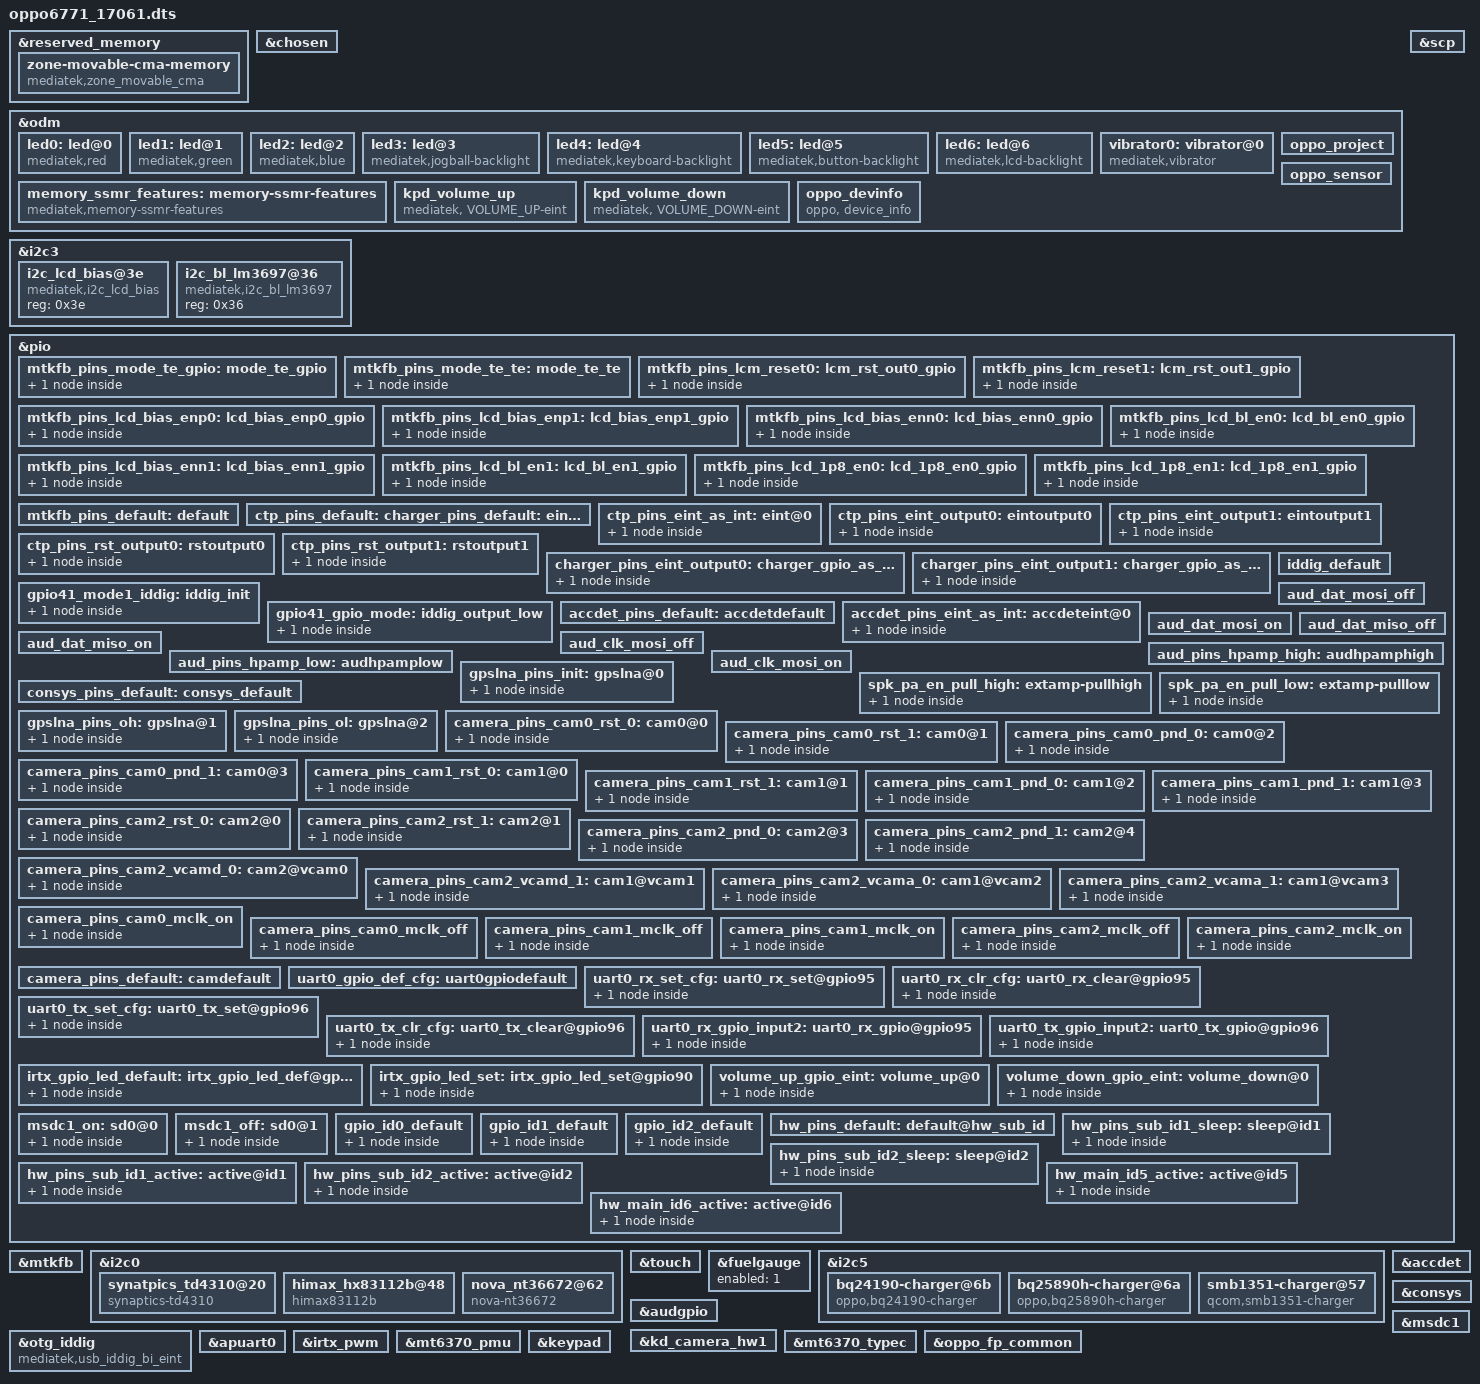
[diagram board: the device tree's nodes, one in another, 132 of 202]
/dts-v1/;
/plugin/;
#include <dt-bindings/interrupt-controller/irq.h>
#include <dt-bindings/interrupt-controller/arm-gic.h>
#include <dt-bindings/pinctrl/mt6771-pinfunc.h>

&reserved_memory {
	#address-cells = <2>;
	#size-cells = <2>;
	ranges;

	zone-movable-cma-memory {
		compatible = "mediatek,zone_movable_cma";
		size = <0 0xffc00000>;
		alignment = <0 0x10000000>;
		alloc-ranges = <0 0xc0000000 1 0x00000000>;

	};
};

/* chosen */
&chosen {
	bootargs = "console=tty0 console=ttyMT0,921600n1 root=/dev/ram \
initrd=0x55000000,0x3000000 loglevel=8 \
androidboot.selinux=permissive androidboot.hardware=mt6771 \
initcall_debug=1";
	/* fpga may has no lk, we need to specify display info here */
	/* fb buffer is reserved using this dts by memory node above */

	atag,videolfb-fb_base_l = <0x5e605000>;
	atag,videolfb-fb_base_h = <0x0>;
	atag,videolfb-islcmfound = <1>;
	atag,videolfb-islcm_inited = <0>;
	atag,videolfb-fps= <6000>;
	atag,videolfb-vramSize= <0x017bb000>;
	atag,videolfb-lcmname= "nt35595_fhd_dsi_cmd_truly_nt50358_drv";
};

&odm {
//#ifdef VENDOR_EDIT
/* Qiao.Hu@BSP.BaseDrv.CHG.Basic, 2017/12/05, Add for charging dtsi */
#include "bat_setting/oppo_17331_mt6771_battery_prop_ext.dtsi"
//endif
	led0:led@0 {
		compatible = "mediatek,red";
		led_mode = <0>;
		data = <1>;
		pwm_config = <0 0 0 0 0>;
	};
	led1:led@1 {
		compatible = "mediatek,green";
		led_mode = <0>;
		data = <1>;
		pwm_config = <0 0 0 0 0>;
	};
	led2:led@2 {
		compatible = "mediatek,blue";
		led_mode = <0>;
		data = <1>;
		pwm_config = <0 0 0 0 0>;
	};
	led3:led@3 {
		compatible = "mediatek,jogball-backlight";
		led_mode = <0>;
		data = <1>;
		pwm_config = <0 0 0 0 0>;
	};
	led4:led@4 {
		compatible = "mediatek,keyboard-backlight";
		led_mode = <0>;
		data = <1>;
		pwm_config = <0 0 0 0 0>;
	};
	led5:led@5 {
		compatible = "mediatek,button-backlight";
		led_mode = <0>;
		data = <1>;
		pwm_config = <0 0 0 0 0>;
	};
	led6:led@6 {
		compatible = "mediatek,lcd-backlight";
		/* #ifndef VENDOR_EDIT */
		/* LiPing-m@PSW.MM.Display.LCD.Machine, 2017/11/03, Add for porting 17331 lcd driver */
		/* led_mode = <5>; */
		/* #else VENDOR_EDIT */
		led_mode = <4>;
		/* #endif VENDOR_EDIT */
		data = <1>;
		pwm_config = <0 3 0 0 0>;
	};
	vibrator0:vibrator@0 {
		compatible = "mediatek,vibrator";
//#ifdef VENDOR_EDIT
//Tong.han@Bsp.Group.Tp,2016/12/16, Modify for vibrator enhance even vibra_time below 9ms
		vib_timer = <30>;
		vib_limit = <0>;
//#else
//		vib_timer = <25>;
//		vib_limit = <9>;
//#endif
//#ifndef VENDOR_EDIT
//Fuchun.Liao@BSP.CHG.Basic 2017/01/04 modify for vib_vol from 2800mv to 3000mv
		//vib_vol= <9>;
//#else
		vib_vol= <11>;
//#endif /* VENDOR_EDIT */
	};
	memory_ssmr_features: memory-ssmr-features {
		compatible = "mediatek,memory-ssmr-features";
		svp-size = <0 0>;
		iris-recognition-size = <0 0>;
		2d_fr-size = <0 0>;
		tui-size = <0 0>;
		wfd-size = <0 0>;
		prot-sharedmem-size = <0 0>;
	};
//#ifndef VENDOR_EDIT
//#Fuchun.Liao@BSP.CHG.Basic 2017/11/22 modify for not use typec
/*
	usb_c_pinctrl:usb_c_pinctrl {
		compatible = "mediatek,usb_c_pinctrl";
	};
*/
//#endif
//ifdef VENDOR_EDIT
/* Bin.Li@EXP.BSP.bootloader.bootflow, 2017/05/16, Add volume up and down */	
	kpd_volume_up:kpd_volume_up {
		compatible = "mediatek, VOLUME_UP-eint";
		interrupt-parent = <&pio>;
		interrupts = <20 IRQ_TYPE_EDGE_FALLING 20 0>;
		debounce = <32000>;
		status = "okay";
	};

	kpd_volume_down:kpd_volume_down {
		compatible = "mediatek, VOLUME_DOWN-eint";
		interrupt-parent = <&pio>;
		interrupts = <94 IRQ_TYPE_EDGE_FALLING 94 0>;
		debounce = <32000>;
		status = "okay";
	};

//#endif





//#ifdef VENDOR_EDIT
/*Bin.Li@EXP.BSP.bootloader.bootflow, 2017/05/15, Add for oppo project */
	oppo_project:oppo_project {
		nProject = <0>;
		nModem = <0>;
		nOperator = <0>;
		nPCBVersion = <0>;
	};
//#endif /*VENDOR_EDIT*/

//#ifdef VENDOR_EDIT
/*Fei.Mo@PSW.BSP.Sensor, 2017/12/18, Add for sensor calibration paramaters */
	oppo_sensor:oppo_sensor {
		gain_als = <0>;
		prox_offset = <0 0>;
		gsensor_sign = <0 0 0>; //1 represent negtive, 0 positive
		gsensor_offset = <0 0 0>;
		gyro_sign = <0 0 0>;//1 represent negtive, 0 positive
		gyro_offset = <0 0 0>;
	};
//#endif /*VENDOR_EDIT*/

//ifdef VENDOR_EDIT
/* Bin.Li@EXP.BSP.bootloader.bootflow, 2017/07/07, Add device-info */
	oppo_devinfo:oppo_devinfo {
		compatible = "oppo, device_info";
	};
//endif
	
};

&scp {
	core_1 = "enable";
	scp_sramSize = <0x00080000>;     /* scp_A_sram_size */
};


/* #ifdef VENDOR_EDIT */
/* LiPing-m@PSW.MM.Display.LCD.Machine, 2017/11/03, Add for porting 17331 lcd driver */
&i2c3 {
    #address-cells = <1>;
    #size-cells = <0>;

       i2c_lcd_bias@3e {
               compatible = "mediatek,i2c_lcd_bias";
               reg = <0x3e>;
               status = "okay";
       };
       i2c_bl_lm3697@36 {
               compatible = "mediatek,i2c_bl_lm3697";
               reg = <0x36>;
               status = "okay";
       };
};

&pio {

	mtkfb_pins_mode_te_gpio: mode_te_gpio {
		pins_cmd_dat {
			pins = <PINMUX_GPIO44__FUNC_GPIO44>;
	};
		};

	mtkfb_pins_mode_te_te: mode_te_te {
		pins_cmd_dat {
			pins = <PINMUX_GPIO44__FUNC_DSI_TE>;
		};
};

	mtkfb_pins_lcm_reset0: lcm_rst_out0_gpio {
		pins_cmd_dat {
			pins = <PINMUX_GPIO45__FUNC_GPIO45>;
			slew-rate = <1>;
			output-low;
		};
};

	mtkfb_pins_lcm_reset1: lcm_rst_out1_gpio {
		pins_cmd_dat {
			pins = <PINMUX_GPIO45__FUNC_GPIO45>;
			slew-rate = <1>;
			output-high;
		};
};

	mtkfb_pins_lcd_bias_enp0: lcd_bias_enp0_gpio {
		pins_cmd_dat {
			pins = <PINMUX_GPIO23__FUNC_GPIO23>;
			slew-rate = <1>;
			output-low;
		};
};

	mtkfb_pins_lcd_bias_enp1: lcd_bias_enp1_gpio {
		pins_cmd_dat {
			pins = <PINMUX_GPIO23__FUNC_GPIO23>;
			slew-rate = <1>;
			output-high;
		};
	};

	mtkfb_pins_lcd_bias_enn0: lcd_bias_enn0_gpio {
		pins_cmd_dat {
			pins = <PINMUX_GPIO24__FUNC_GPIO24>;
			slew-rate = <1>;
			output-low;
		};
	};

	mtkfb_pins_lcd_bias_enn1: lcd_bias_enn1_gpio {
		pins_cmd_dat {
			pins = <PINMUX_GPIO24__FUNC_GPIO24>;
			slew-rate = <1>;
			output-high;
		};
	};

	mtkfb_pins_lcd_bl_en0: lcd_bl_en0_gpio {
		pins_cmd_dat {
			pins = <PINMUX_GPIO66__FUNC_GPIO66>;
			slew-rate = <1>;
			output-low;
		};
	};

	mtkfb_pins_lcd_bl_en1: lcd_bl_en1_gpio {
		pins_cmd_dat {
			pins = <PINMUX_GPIO66__FUNC_GPIO66>;
			slew-rate = <1>;
			output-high;
		};
	};

	mtkfb_pins_lcd_1p8_en0: lcd_1p8_en0_gpio {
		pins_cmd_dat {
			pins = <PINMUX_GPIO65__FUNC_GPIO65>;
			slew-rate = <1>;
			output-low;
		};
	};

	mtkfb_pins_lcd_1p8_en1: lcd_1p8_en1_gpio {
		pins_cmd_dat {
			pins = <PINMUX_GPIO65__FUNC_GPIO65>;
			slew-rate = <1>;
			output-high;
		};
	};

	mtkfb_pins_default: default {
};
};

&mtkfb {
	pinctrl-names = "default", "mode_te_gpio", "mode_te_te", "lcm_rst_out0_gpio",
	"lcm_rst_out1_gpio", "lcd_bias_enp0_gpio", "lcd_bias_enp1_gpio",
	"lcd_bias_enn0_gpio","lcd_bias_enn1_gpio","lcd_bl_en0_gpio",
	"lcd_bl_en1_gpio","lcd_1p8_en0_gpio","lcd_1p8_en1_gpio";
	pinctrl-0 = <&mtkfb_pins_default>;
	pinctrl-1 = <&mtkfb_pins_mode_te_gpio>;
	pinctrl-2 = <&mtkfb_pins_mode_te_te>;
	pinctrl-3 = <&mtkfb_pins_lcm_reset0>;
	pinctrl-4 = <&mtkfb_pins_lcm_reset1>;
	pinctrl-5 = <&mtkfb_pins_lcd_bias_enp0>;
	pinctrl-6 = <&mtkfb_pins_lcd_bias_enp1>;
	pinctrl-7 = <&mtkfb_pins_lcd_bias_enn0>;
	pinctrl-8 = <&mtkfb_pins_lcd_bias_enn1>;
	pinctrl-9 = <&mtkfb_pins_lcd_bl_en0>;
	pinctrl-10 = <&mtkfb_pins_lcd_bl_en1>;
	pinctrl-11 = <&mtkfb_pins_lcd_1p8_en0>;
	pinctrl-12 = <&mtkfb_pins_lcd_1p8_en1>;
	status = "okay";
};
/* #endif VENDOR_EDIT */

//#ifdef VENDOR_EDIT
/* Cong.Dai@PSW.BSP.TP,  2017/06/21, Add for TP td4310*/
&i2c0 {
	#address-cells = <1>;
	#size-cells = <0>;

    synatpics_td4310@20 {
        compatible = "synaptics-td4310";
        reg = <0x20>;
        status = "okay";
        chip-name = "TD4310";

        interrupt-parent = <&pio>;
        interrupts = <1 0x2008 1 0>;

        irq-gpio = <&pio 1 0x2008>;
        //reset-gpio = <&pio 10>;

        pinctrl-names = "default";
        //pinctrl-0 = "&ts_int_active &ts_reset_active";

        touchpanel,max-num-support = <10>;
        touchpanel,tx-rx-num = <18 32>;
        touchpanel,panel-coords = <1080 2160>;
        touchpanel,display-coords = <1080 2160>;

        incell_screen;
        edge_limit_support;
        black_gesture_support;
        //spurious_fingerprint_support;
        //lcd_trigger_fp_check;
        black_gesture_test_support;
        fw_update_app_support;

        /*
        *Virtual Key Config:
        *1:touchpanel,button-type: <virtualkey_type  supportted_button-map>
        *virtualkey_type:
        *Type 1: using board_properties
        *Type 2: using same IC (button zone&& touch zone are seprate)
        *Type 3: using diffrent IC (button zone&& touch zone are seprate)
        *Type 4: No need of virtual key process
        *supportted_button-map:select|menu|home|back
        *
        *2:touchpanel,button-map
        *type (X1,Y1)(X2,Y2)(X3,Y3)(Width_X,Hight_Y)--Only when button-type is 0
        */

        touchpanel,button-type = <2 0x05>;
    };

/* MingQiang.Guo@PSW.BSP.TP,  2017/12/07, Add for TP himax*/
    himax_hx83112b@48 {
        compatible = "himax83112b";
        reg = <0x48>;
        status = "okay";
        chip-name = "HIMAX83112B";

        interrupt-parent = <&pio>;
        interrupts = <1 0x2008 1 0>;

        irq-gpio = <&pio 1 0x2002>;
        reset-gpio = <&pio 42 0x00>;

        pinctrl-names = "default";
        //pinctrl-0 = "&ts_int_active &ts_reset_active";

        touchpanel,max-num-support = <10>;
        touchpanel,tx-rx-num = <16 36>;
        touchpanel,panel-coords = <1080 2280>;
        touchpanel,display-coords = <1080 2280>;

        incell_screen;
        edge_limit_support;
        black_gesture_support;
        fw_update_app_support;

        /*Guohua.Zhong@BSP.TP.Function, 2018/01/04, Add for informing tp driver of usb state*/
        charger_pump_support;
        //spurious_fingerprint_support;
        //lcd_trigger_fp_check;
        black_gesture_test_support;
        touchpanel,button-type = <2 0x05>;
    };

	/* Wanghao@PSW.BSP.TP, 2018/01/22, Add for TP novatek 36672*/
	nova_nt36672@62 {
		compatible = "nova-nt36672";
		reg = <0x62>;
		status = "okay";
		chip-name = "NT36672";

		interrupt-parent = <&pio>;
		interrupts = <1 0x00 1 0>;
		irq-gpio = <&pio 1 0x2001>;

		touchpanel,max-num-support = <10>;
		touchpanel,tx-rx-num = <18 32>;
		touchpanel,panel-coords = <1080 2160>;
		touchpanel,display-coords = <1080 2160>;

		incell_screen;
		edge_limit_support;
		black_gesture_support;
		charger_pump_support;
		//spurious_fingerprint_support;
		//lcd_trigger_fp_check;
		black_gesture_test_support;
		fw_update_app_support;
		//game_switch_support;

		/*
		*Virtual Key Config:
		*1:touchpanel,button-type: <virtualkey_type  supportted_button-map>
		*virtualkey_type:
		*Type 1: using board_properties
		*Type 2: using same IC (button zone&& touch zone are seprate)
		*Type 3: using diffrent IC (button zone&& touch zone are seprate)
		*Type 4: No need of virtual key process
		*supportted_button-map:select|menu|home|back
		*
		*2:touchpanel,button-map
		*type (X1,Y1)(X2,Y2)(X3,Y3)(Width_X,Hight_Y)--Only when button-type is 0
		*/

		touchpanel,button-type = <2 0x05>;
	};
};
//#endif /* VENDOR_EDIT */



/* TOUCH start */
&touch {
	tpd-resolution = <1080 1920>;
	use-tpd-button = <0>;
	tpd-key-num = <3>;
	tpd-key-local= <139 172 158 0>;
	tpd-key-dim-local = <90 883 100 40 230 883 100 40 370 883 100 40 0 0 0 0>;
	tpd-max-touch-num = <5>;
	tpd-filter-enable = <1>;
	tpd-filter-pixel-density = <146>;
	tpd-filter-custom-prameters = <0 0 0 0 0 0 0 0 0 0 0 0>;
	tpd-filter-custom-speed = <0 0 0>;
	pinctrl-names = "default", "state_eint_as_int", "state_eint_output0", "state_eint_output1",
		"state_rst_output0", "state_rst_output1";
	pinctrl-0 = <&ctp_pins_default>;
	pinctrl-1 = <&ctp_pins_eint_as_int>;
	pinctrl-2 = <&ctp_pins_eint_output0>;
	pinctrl-3 = <&ctp_pins_eint_output1>;
	pinctrl-4 = <&ctp_pins_rst_output0>;
	pinctrl-5 = <&ctp_pins_rst_output1>;
	status = "okay";
};
&pio {
	ctp_pins_default: eint0default {
	};
	ctp_pins_eint_as_int: eint@0 {
		pins_cmd_dat {
			pins = <PINMUX_GPIO1__FUNC_GPIO1>;
			slew-rate = <0>;
			bias-disable;
		};
	};
	ctp_pins_eint_output0: eintoutput0 {
		pins_cmd_dat {
			pins = <PINMUX_GPIO1__FUNC_GPIO1>;
			slew-rate = <1>;
			output-low;
		};
	};
	ctp_pins_eint_output1: eintoutput1 {
		pins_cmd_dat {
			pins = <PINMUX_GPIO1__FUNC_GPIO1>;
			slew-rate = <1>;
			output-high;
		};
	};
	ctp_pins_rst_output0: rstoutput0 {
		pins_cmd_dat {
			pins = <PINMUX_GPIO2__FUNC_GPIO2>;
			slew-rate = <1>;
			output-low;
		};
	};
	ctp_pins_rst_output1: rstoutput1 {
		pins_cmd_dat {
			pins = <PINMUX_GPIO2__FUNC_GPIO2>;
			slew-rate = <1>;
			output-high;
		};
	};
};
/* TOUCH end */
//#ifdef VENDOR_EDIT
//PengNan@BSP.CHG.Basic, 2017/09/07, add for compatabling two fuelgauge.
&fuelgauge{
	enabled = <1>;
};
//#endif
//#ifdef VENDOR_EDIT
/* Qiao.Hu@BSP.BaseDrv.CHG.Basic, 2017/11/19, Add for charging */
&i2c5 {
	bq24190-charger@6b {
		status = "okay";
		compatible = "oppo,bq24190-charger";
		reg = <0x6b>;
		chip-name = "BQ24190";
        	interrupt-parent = <&pio>;
        	interrupts = <91 0x2 91 0>;
		pinctrl-names = "default", "charger_gpio_as_output_low", "charger_gpio_as_output_high";
		pinctrl-0 = <&charger_pins_default>;
		pinctrl-1 = <&charger_pins_eint_output0>;
		pinctrl-2 = <&charger_pins_eint_output1>;
		qcom,input_current_charger_ma = <2000>;
		qcom,input_current_usb_ma = <500>;
		qcom,input_current_led_ma = <900>;
		qcom,input_current_led_ma_forcmcc = <500>;
		qcom,input_current_camera_ma = <1200>;

		qcom,input_current_calling_ma = <1500>;
		qcom,iterm-disabled = <0>;
		qcom,iterm-ma = <165>;
		qcom,recharge-mv = <100>;
		qcom,external_gauge;
		qcom,batt_capacity_mah = <3300>;
		qcom,removed_bat_decidegc = <190>;  /* < -19C */
		qcom,cold_bat_decidegc = <30>;  /* -3C ~ 0C */
		qcom,temp_cold_vfloat_mv = <3980>;
		qcom,temp_cold_fastchg_current_ma = <364>;
		qcom,little_cold_bat_decidegc = <0>;	/* 0C ~ 5C */
		qcom,temp_little_cold_vfloat_mv = <4370>;
		qcom,temp_little_cold_fastchg_current_ma = <463>;
		qcom,cool_bat_decidegc = <50>;	/* 5C ~ 12C */
		qcom,temp_cool_vfloat_mv = <4370>;
		qcom,temp_cool_fastchg_current_ma_high = <793>;
		qcom,temp_cool_fastchg_current_ma_low = <463>;
		qcom,little_cool_bat_decidegc = <120>;	/* 12C ~ 22C */
		qcom,temp_little_cool_vfloat_mv = <4370>;
		qcom,temp_little_cool_fastchg_current_ma = <1453>;
		qcom,normal_bat_decidegc = <220>;	/* 22C ~ 45C */
		qcom,temp_normal_fastchg_current_ma = <2113>;
		qcom,temp_normal_vfloat_mv_normalchg = <4370>;
		qcom,temp_normal_vfloat_mv_voocchg = <4370>;
		qcom,warm_bat_decidegc = <450>;		/* 45C ~ 53C */
		qcom,temp_warm_vfloat_mv = <4080>;
		qcom,temp_warm_fastchg_current_ma = <793>;
		qcom,hot_bat_decidegc = <530>;
		qcom,non_standard_vfloat_mv = <4000>;
		qcom,non_standard_fastchg_current_ma = <512>;

		qcom,non_standard_vfloat_sw_limit = <3950>;
		qcom,cold_vfloat_sw_limit = <3930>;
		qcom,little_cold_vfloat_sw_limit = <4320>;
		qcom,cool_vfloat_sw_limit = <4320>;
		qcom,little_cool_vfloat_sw_limit = <4320>;
		qcom,normal_vfloat_sw_limit = <4320>;
		qcom,warm_vfloat_sw_limit = <4030>;
		
		qcom,non_standard_vfloat_over_sw_limit = <3980>;
		qcom,cold_vfloat_over_sw_limit = <3980>;
		qcom,little_cold_vfloat_over_sw_limit = <4390>;
		qcom,cool_vfloat_over_sw_limit = <4390>;
		qcom,little_cool_vfloat_over_sw_limit = <4390>;
		qcom,normal_vfloat_over_sw_limit = <4390>;
		qcom,warm_vfloat_over_sw_limit = <4080>;
		qcom,sw_vfloat_over_protect_enable;

		qcom,max_chg_time_sec = <36000>;
		qcom,charger_hv_thr = <5800>;
		qcom,charger_lv_thr = <3400>;
		qcom,vbatt_full_thr = <4400>;
		qcom,vbatt_hv_thr = <4500>;
		qcom,vfloat_step_mv = <16>;
	//	qcom,suspend_after_full;
		qcom,check_batt_full_by_sw;
		qcom,chg_ctrl_by_calling;
		qcom,chg_ctrl_by_lcd;
		qcom,chg_ctrl_by_camera;
		/*Qiao.Hu@EXP.BSP.LCD.Machine, 2017/07/20, Add  function for chargerid distinguish*/
		qcom,usb_shell_ctrl;
		qcom,usb_enum_enable;
		qcom,usb_switch_gpio 		= <&pio 9 0x00>;
		qcom,usb_shell_ctrl_gpio 			= <&pio 21 0x00>;
	};
	bq25890h-charger@6a {
		status = "okay";
		compatible = "oppo,bq25890h-charger";
		reg = <0x6a>;
		chip-name = "BQ25890H";
        interrupt-parent = <&pio>;
        interrupts = <91 0x2 91 0>;
		pinctrl-names = "default", "charger_gpio_as_output_low", "charger_gpio_as_output_high", "ship_sleep", "ship_active";
		pinctrl-0 = <&charger_pins_default>;
		pinctrl-1 = <&charger_pins_eint_output0>;
		pinctrl-2 = <&charger_pins_eint_output1>;
		pinctrl-3 = <&ship_sleep_gpio>;
		pinctrl-4 = <&ship_active_gpio>;
		qcom,input_current_charger_ma = <2000>;
		qcom,input_current_usb_ma = <500>;
		qcom,input_current_led_ma = <900>;
		qcom,input_current_led_ma_forcmcc = <500>;
		qcom,input_current_camera_ma = <1200>;

		qcom,input_current_calling_ma = <1500>;
		qcom,iterm-disabled = <0>;
		qcom,iterm-ma = <165>;
		qcom,recharge-mv = <100>;
		qcom,external_gauge;
		qcom,batt_capacity_mah = <3300>;
		qcom,removed_bat_decidegc = <190>;  /* < -19C */
		qcom,cold_bat_decidegc = <30>;  /* -3C ~ 0C */
		qcom,temp_cold_vfloat_mv = <3980>;
		qcom,temp_cold_fastchg_current_ma = <364>;
		qcom,little_cold_bat_decidegc = <0>;	/* 0C ~ 5C */
		qcom,temp_little_cold_vfloat_mv = <4370>;
		qcom,temp_little_cold_fastchg_current_ma = <463>;
		qcom,cool_bat_decidegc = <50>;	/* 5C ~ 12C */
		qcom,temp_cool_vfloat_mv = <4370>;
		qcom,temp_cool_fastchg_current_ma_high = <793>;
		qcom,temp_cool_fastchg_current_ma_low = <463>;
		qcom,little_cool_bat_decidegc = <120>;	/* 12C ~ 22C */
		qcom,temp_little_cool_vfloat_mv = <4370>;
		qcom,temp_little_cool_fastchg_current_ma = <1453>;
		qcom,normal_bat_decidegc = <220>;	/* 22C ~ 45C */
		qcom,temp_normal_fastchg_current_ma = <2113>;
		qcom,temp_normal_vfloat_mv_normalchg = <4370>;
		qcom,temp_normal_vfloat_mv_voocchg = <4370>;
		qcom,warm_bat_decidegc = <450>;		/* 45C ~ 53C */
		qcom,temp_warm_vfloat_mv = <4080>;
		qcom,temp_warm_fastchg_current_ma = <793>;
		qcom,hot_bat_decidegc = <530>;
		qcom,non_standard_vfloat_mv = <4000>;
		qcom,non_standard_fastchg_current_ma = <512>;

		qcom,non_standard_vfloat_sw_limit = <3950>;
		qcom,cold_vfloat_sw_limit = <3930>;
		qcom,little_cold_vfloat_sw_limit = <4320>;
		qcom,cool_vfloat_sw_limit = <4320>;
		qcom,little_cool_vfloat_sw_limit = <4320>;
		qcom,normal_vfloat_sw_limit = <4320>;
		qcom,warm_vfloat_sw_limit = <4030>;
		
		qcom,non_standard_vfloat_over_sw_limit = <3980>;
		qcom,cold_vfloat_over_sw_limit = <3980>;
		qcom,little_cold_vfloat_over_sw_limit = <4390>;
		qcom,cool_vfloat_over_sw_limit = <4390>;
		qcom,little_cool_vfloat_over_sw_limit = <4390>;
		qcom,normal_vfloat_over_sw_limit = <4390>;
		qcom,warm_vfloat_over_sw_limit = <4080>;
		qcom,sw_vfloat_over_protect_enable;

		qcom,max_chg_time_sec = <36000>;
		qcom,charger_hv_thr = <5800>;
		qcom,charger_lv_thr = <3400>;
		qcom,vbatt_full_thr = <4400>;
		qcom,vbatt_hv_thr = <4500>;
		qcom,vfloat_step_mv = <16>;
	//	qcom,suspend_after_full;
		qcom,check_batt_full_by_sw;
		qcom,chg_ctrl_by_calling;
		qcom,chg_ctrl_by_lcd;
		qcom,chg_ctrl_by_camera;
		/*Qiao.Hu@EXP.BSP.LCD.Machine, 2017/07/20, Add  function for chargerid distinguish*/
		qcom,usb_shell_ctrl;
		qcom,usb_switch_gpio 		= <&pio 9 0x00>;
		qcom,ship_gpio 		= <&pio 152 0x00>;
		qcom,usb_shell_ctrl_gpio 			= <&pio 21 0x00>;
	};
	smb1351-charger@57 {
		status = "okay";
		compatible = "qcom,smb1351-charger";
		reg = <0x57>;
		pinctrl-names = "default", "charger_gpio_as_output_low", "charger_gpio_as_output_high", "ship_sleep", "ship_active";
		pinctrl-0 = <&charger_pins_default>;
		pinctrl-1 = <&charger_pins_eint_output0>;
		pinctrl-2 = <&charger_pins_eint_output1>;
		pinctrl-3 = <&ship_sleep_gpio>;
		pinctrl-4 = <&ship_active_gpio>;
		qcom,input_current_charger_ma = <2000>;
		qcom,input_current_usb_ma = <500>;
		qcom,input_current_led_ma = <900>;
		qcom,input_current_led_ma_forcmcc = <500>;
		qcom,input_current_camera_ma = <1200>;

		qcom,input_current_calling_ma = <1500>;
		qcom,iterm-disabled = <0>;
		qcom,iterm-ma = <172>;
		qcom,recharge-mv = <100>;
		qcom,external_gauge;
		qcom,batt_capacity_mah = <3450>;
		qcom,removed_bat_decidegc = <190>;  /* < -19C */
		qcom,cold_bat_decidegc = <30>;  /* -3C ~ 0C */
		qcom,temp_cold_vfloat_mv = <3980>;
		qcom,temp_cold_fastchg_current_ma = <364>;
		qcom,little_cold_bat_decidegc = <0>;	/* 0C ~ 5C */
		qcom,temp_little_cold_vfloat_mv = <4380>;
		qcom,temp_little_cold_fastchg_current_ma = <485>;
		qcom,cool_bat_decidegc = <50>;	/* 5C ~ 12C */
		qcom,temp_cool_vfloat_mv = <4380>;
		qcom,temp_cool_fastchg_current_ma_high = <830>;
		qcom,temp_cool_fastchg_current_ma_low = <485>;
		qcom,little_cool_bat_decidegc = <120>;	/* 12C ~ 22C */
		qcom,temp_little_cool_vfloat_mv = <4380>;
		qcom,temp_little_cool_fastchg_current_ma = <1520>;
		qcom,normal_bat_decidegc = <220>;	/* 22C ~ 45C */
		qcom,temp_normal_fastchg_current_ma = <2210>;
		qcom,temp_normal_vfloat_mv_normalchg = <4380>;
		qcom,temp_normal_vfloat_mv_voocchg = <4380>;
		qcom,warm_bat_decidegc = <450>;		/* 45C ~ 53C */
		qcom,temp_warm_vfloat_mv = <4080>;
		qcom,temp_warm_fastchg_current_ma = <830>;
		qcom,hot_bat_decidegc = <530>;
		qcom,non_standard_vfloat_mv = <4000>;
		qcom,non_standard_fastchg_current_ma = <512>;

		qcom,non_standard_vfloat_sw_limit = <3960>;
		qcom,cold_vfloat_sw_limit = <3940>;
		qcom,little_cold_vfloat_sw_limit = <4320>;
		qcom,cool_vfloat_sw_limit = <4320>;
		qcom,little_cool_vfloat_sw_limit = <4320>;
		qcom,normal_vfloat_sw_limit = <4320>;
		qcom,warm_vfloat_sw_limit = <4030>;
		
		qcom,non_standard_vfloat_over_sw_limit = <3980>;
		qcom,cold_vfloat_over_sw_limit = <3980>;
		qcom,little_cold_vfloat_over_sw_limit = <4380>;
		qcom,cool_vfloat_over_sw_limit = <4380>;
		qcom,little_cool_vfloat_over_sw_limit = <4380>;
		qcom,normal_vfloat_over_sw_limit = <4380>;
		qcom,warm_vfloat_over_sw_limit = <4080>;
		qcom,sw_vfloat_over_protect_enable;

		qcom,max_chg_time_sec = <36000>;
		qcom,charger_hv_thr = <5800>;
		qcom,charger_lv_thr = <3400>;
		qcom,vbatt_full_thr = <4400>;
		qcom,vbatt_hv_thr = <4500>;
		qcom,vfloat_step_mv = <16>;
	//	qcom,suspend_after_full;
		qcom,check_batt_full_by_sw;
		qcom,chg_ctrl_by_calling;
		qcom,chg_ctrl_by_lcd;
		qcom,chg_ctrl_by_camera;
		/*Qiao.Hu@EXP.BSP.LCD.Machine, 2017/07/20, Add  function for chargerid distinguish*/
		qcom,usb_shell_ctrl;
		qcom,usb_switch_gpio 		= <&pio 9 0x00>;
		qcom,usb_shell_ctrl_gpio 			= <&pio 21 0x00>;
	};
};

&pio {
	charger_pins_default: eint0default {
	};
	charger_pins_eint_output0: charger_gpio_as_output_low {
		pins_cmd_dat {
			pins = <PINMUX_GPIO9__FUNC_GPIO9>;
			slew-rate = <1>;
			output-low;
		};
	};
	charger_pins_eint_output1: charger_gpio_as_output_high {
		pins_cmd_dat {
			pins = <PINMUX_GPIO9__FUNC_GPIO9>;
			slew-rate = <1>;
			output-high;
		};
	};
};
//#endif /* VENDOR_EDIT */
/* Qiao.Hu@@Prd6.BaseDrv.USB.Basic, 2017/07/25, Add for otg */
&otg_iddig {
	/* Qiao.Hu@EXP.BSP.CHG.basic, 2017/05/09, Add for otg support */
	compatible = "mediatek,usb_iddig_bi_eint";
	pinctrl-names = "iddig_default", "iddig_init", "iddig_output_low" ;
	pinctrl-0 = <&iddig_default>;
	pinctrl-1 = <&gpio41_mode1_iddig>;
	pinctrl-2 = <&gpio41_gpio_mode>;
	status = "okay";
    	/* Qiao.Hu@EXP.BSP.CHG.basic, 2017/05/25, Add for OTG GPIO */
	qcom,otg_switch_gpio = <41>;

};
&pio {
	iddig_default: iddig_default {
	};
	//#ifdef VENDOR_EDIT
	/* Qiao.Hu@EXP.BSP.CHG.basic, 2017/11/28, Add for otg support */
	gpio41_mode1_iddig: iddig_init {
		pins_cmd_dat {
			pins = <PINMUX_GPIO41__FUNC_IDDIG>;
			slew-rate = <0>;
			bias-pull-up = <101>;
		};
	};
	gpio41_gpio_mode: iddig_output_low {
		pins_cmd_dat {
			pins = <PINMUX_GPIO41__FUNC_GPIO41>;
			slew-rate = <1>;
			output-low;
		};
	};

	//#endif /* VENDOR_EDIT */
};


/* accdet start */
&accdet {
	/* accdet micbias voltage: 0x07,2.7v;0x05,2.5v;0x02,1.9v */
	//#ifdef VENDOR_EDIT
	//Yongzhi.Zhang@PSW.MM.AudioDriver.Codec, 2018/03/10,
	//modify for changing micbias vol to 2.7V for headset mic
	accdet-mic-vol = <7>;
	//#else /* VENDOR_EDIT */
	//accdet-mic-vol = <6>;
	//#endif /* VENDOR_EDIT */
	headset-mode-setting = <0x500 0x500 1 0x1f0 0x800 0x800 0x20 0x44>;
	accdet-plugout-debounce = <1>;
	/*1:ACC mode, 2:low cost without in bias, 6:low cost with in bias*/
	//#ifdef VENDOR_EDIT
	//Yongzhi.Zhang@PSW.MM.AudioDriver.HeadsetDet, 2017/12/28, Modify for ACC MODE
	accdet-mic-mode = <1>;
	//#else /* VENDOR_EDIT */
	//accdet-mic-mode = <2>;
	//#endif /* VENDOR_EDIT */
	/* eint_level_trigger: 8,LEVEL_LOW(default);4,LEVEL_HIGH;others,LEVEL_LOW */
	headset-eint-level-pol = <8>;
	/*0--MD_MAX--UP_MAX--DW_MAX*/
	//#ifdef VENDOR_EDIT
	//Yongzhi.Zhang@PSW.MM.AudioDriver.HeadsetDet, 2017/14/14, Modify for support headset key
	headset-three-key-threshold = <0 82 170 306>;
	//#else /* VENDOR_EDIT */
	//headset-three-key-threshold = <0 80 220 400>;
	//#endif /* VENDOR_EDIT */
	headset-three-key-threshold-CDD = <0 121 192 600>;
	/*0--MD_MAX--VOICE_MAX--UP_MAX--DW_MAX*/
	headset-four-key-threshold = <0 58 121 192 400>;
	/*moisture external resister ohm*/
	moisture-external-r = <2000000>;
	/*moisture internal resister ohm*/
	moisture-internal-r = <47000>;
	/*moisture of water resister ohm*/
	moisture-water-r = <10000>;
	/* ACCDET GPIO standardization ACC mode no use */
	pinctrl-names = "default", "state_eint_as_int";
	pinctrl-0 = <&accdet_pins_default>;
	pinctrl-1 = <&accdet_pins_eint_as_int>;
	status = "okay";
};
&pio {
	accdet_pins_default: accdetdefault {
	};
	accdet_pins_eint_as_int: accdeteint@0 {
		pins_cmd_dat {
			/*pins = <PINMUX_GPIO7__FUNC_GPIO7>;*/
			slew-rate = <0>;
			bias-disable;
		};
	};
};
/* accdet end */

//#ifdef VENDOR_EDIT
/* Yongzhi.Zhang@PSW.MM.AudioDriver.Machine, 2017/11/22,
 * Modify for audio gpio config */
&audgpio {
	pinctrl-names = "aud_dat_mosi_off",
			"aud_dat_mosi_on",
			"aud_dat_miso_off",
			"aud_dat_miso_on",
			"hpamp-pullhigh",
			"hpamp-pulllow",
			"aud_clk_mosi_off",
			"aud_clk_mosi_on",
			"extamp-pullhigh",
			"extamp-pulllow";
	pinctrl-0 = <&aud_dat_mosi_off>;
	pinctrl-1 = <&aud_dat_mosi_on>;
	pinctrl-2 = <&aud_dat_miso_off>;
	pinctrl-3 = <&aud_dat_miso_on>;
	pinctrl-4 = <&aud_pins_hpamp_high>;
	pinctrl-5 = <&aud_pins_hpamp_low>;
	pinctrl-6 = <&aud_clk_mosi_off>;
	pinctrl-7 = <&aud_clk_mosi_on>;
	pinctrl-8 = <&spk_pa_en_pull_high>;
	pinctrl-9 = <&spk_pa_en_pull_low>;
	gpio_spk_pa_en = <&pio 153 0>;
	status = "okay";
};

&pio {
	aud_dat_mosi_off: aud_dat_mosi_off {
	};

	aud_dat_mosi_on: aud_dat_mosi_on {
	};

	aud_dat_miso_off: aud_dat_miso_off {
	};

	aud_dat_miso_on: aud_dat_miso_on {
	};

	aud_pins_hpamp_high: audhpamphigh {
	};

	aud_pins_hpamp_low: audhpamplow {
	};

	aud_clk_mosi_off: aud_clk_mosi_off {
	};

	aud_clk_mosi_on: aud_clk_mosi_on {
	};

	spk_pa_en_pull_high: extamp-pullhigh {
		pins_cmd_dat {
			pins = <PINMUX_GPIO153__FUNC_GPIO153>;
			slew-rate = <1>;
			output-high;
		};
	};

	spk_pa_en_pull_low: extamp-pulllow {
		pins_cmd_dat {
			pins = <PINMUX_GPIO153__FUNC_GPIO153>;
			slew-rate = <1>;
			output-low;
		};
	};
};
//#endif /* VENDOR_EDIT */

/* CONSYS GPIO standardization */
&pio {
	consys_pins_default: consys_default {
	};
	gpslna_pins_init: gpslna@0 {
		pins_cmd_dat {
			pins = <PINMUX_GPIO169__FUNC_GPIO169>;
			//#ifndef VENDOR_EDIT
			//Wenjie.Liu@PSW.CN.GPS.Hardware.Power.1202743, 2017/12/29,
			//modify for: [GPS_LNA gpio's output direction is out]
			/*
			slew-rate = <0>;
			*/
			//#else /* VENDOR_EDIT */
			slew-rate = <1>;
			//#endif /* VENDOR_EDIT */
			bias-disable;
			output-low;
		};
	};
	gpslna_pins_oh: gpslna@1 {
		pins_cmd_dat {
			pins = <PINMUX_GPIO169__FUNC_GPIO169>;
			slew-rate = <1>;
			output-high;
		};
	};
	gpslna_pins_ol: gpslna@2 {
		pins_cmd_dat {
			pins = <PINMUX_GPIO169__FUNC_GPIO169>;
			slew-rate = <1>;
			output-low;
		};
	};
};
&consys {
	pinctrl-names = "default", "gps_lna_state_init", "gps_lna_state_oh", "gps_lna_state_ol";
	pinctrl-0 = <&consys_pins_default>;
	pinctrl-1 = <&gpslna_pins_init>;
	pinctrl-2 = <&gpslna_pins_oh>;
	pinctrl-3 = <&gpslna_pins_ol>;
	status = "okay";
};
/* CONSYS end */

/* CAMERA GPIO standardization */
&pio {
	camera_pins_cam0_rst_0: cam0@0 {
		pins_cmd_dat {
			pins = <PINMUX_GPIO101__FUNC_GPIO101>;
			slew-rate = <1>; /*direction 0:in, 1:out*/
			output-low;/*direction out used only. output_low or high*/
		};
	};
	camera_pins_cam0_rst_1: cam0@1 {
		pins_cmd_dat {
			pins = <PINMUX_GPIO101__FUNC_GPIO101>;
			slew-rate = <1>;
			output-high;
		};
	};
	camera_pins_cam0_pnd_0: cam0@2 {
		pins_cmd_dat {
			pins = <PINMUX_GPIO97__FUNC_GPIO97>;
			slew-rate = <1>;
			output-low;
		};
	};
	camera_pins_cam0_pnd_1: cam0@3 {
		pins_cmd_dat {
			pins = <PINMUX_GPIO97__FUNC_GPIO97>;
			slew-rate = <1>;
			output-high;
		};
	};
	camera_pins_cam1_rst_0: cam1@0 {
		pins_cmd_dat {
			pins = <PINMUX_GPIO102__FUNC_GPIO102>;
			slew-rate = <1>; /*direction 0:in, 1:out*/
			output-low;/*direction out used only. output_low or high*/
		};
	};
	camera_pins_cam1_rst_1: cam1@1 {
		pins_cmd_dat {
			pins = <PINMUX_GPIO102__FUNC_GPIO102>;
			slew-rate = <1>;
			output-high;
		};
	};
	camera_pins_cam1_pnd_0: cam1@2 {
		pins_cmd_dat {
			pins = <PINMUX_GPIO98__FUNC_GPIO98>;
			slew-rate = <1>;
			output-low;
		};
	};
	camera_pins_cam1_pnd_1: cam1@3 {
		pins_cmd_dat {
			pins = <PINMUX_GPIO98__FUNC_GPIO98>;
			slew-rate = <1>;
			output-high;
		};
	};
	camera_pins_cam2_rst_0: cam2@0 {
		pins_cmd_dat {
			pins = <PINMUX_GPIO109__FUNC_GPIO109>;
			slew-rate = <1>;
			output-low;
		};
	};
	camera_pins_cam2_rst_1: cam2@1 {
		pins_cmd_dat {
			pins = <PINMUX_GPIO109__FUNC_GPIO109>;
			slew-rate = <1>;
			output-high;
		};
	};
	camera_pins_cam2_pnd_0: cam2@3 {
		pins_cmd_dat {
			pins = <PINMUX_GPIO107__FUNC_GPIO107>;
			slew-rate = <1>;
			output-low;
		};
	};
	camera_pins_cam2_pnd_1: cam2@4 {
		pins_cmd_dat {
			pins = <PINMUX_GPIO107__FUNC_GPIO107>;
			slew-rate = <1>;
			output-high;
		};
	};
	camera_pins_cam2_vcamd_0: cam2@vcam0 {
		pins_cmd_dat {
			pins = <PINMUX_GPIO169__FUNC_GPIO169>;
			slew-rate = <1>;
			output-low;
		};
	};
	camera_pins_cam2_vcamd_1: cam1@vcam1 {
		pins_cmd_dat {
			pins = <PINMUX_GPIO169__FUNC_GPIO169>;
			slew-rate = <1>;
			output-high;
		};
	};
	camera_pins_cam2_vcama_0: cam1@vcam2 {
		pins_cmd_dat {
			pins = <PINMUX_GPIO169__FUNC_GPIO169>;
			slew-rate = <1>;
			output-low;
		};
	};
	camera_pins_cam2_vcama_1: cam1@vcam3 {
		pins_cmd_dat {
			pins = <PINMUX_GPIO169__FUNC_GPIO169>;
			slew-rate = <1>;
			output-high;
		};
	};
	camera_pins_cam0_mclk_on: camera_pins_cam0_mclk_on {
		pins_cmd_dat {
			pins = <PINMUX_GPIO99__FUNC_CMMCLK0>;
		};
	};
	camera_pins_cam0_mclk_off: camera_pins_cam0_mclk_off {
		pins_cmd_dat {
			pins = <PINMUX_GPIO99__FUNC_GPIO99>;
		};
	};
	camera_pins_cam1_mclk_off: camera_pins_cam1_mclk_off {
		pins_cmd_dat {
			pins = <PINMUX_GPIO100__FUNC_GPIO100>;
		};
	};
	camera_pins_cam1_mclk_on: camera_pins_cam1_mclk_on {
		pins_cmd_dat {
			pins = <PINMUX_GPIO100__FUNC_CMMCLK1>;
		};
	};
	camera_pins_cam2_mclk_off: camera_pins_cam2_mclk_off {
		pins_cmd_dat {
			pins = <PINMUX_GPIO108__FUNC_GPIO108>;
		};
	};
	camera_pins_cam2_mclk_on: camera_pins_cam2_mclk_on {
		pins_cmd_dat {
			pins = <PINMUX_GPIO108__FUNC_CMMCLK2>;
		};
	};
	camera_pins_default: camdefault {
	};
};
&kd_camera_hw1 {
	pinctrl-names = "default",
			"cam0_rst0", "cam0_rst1",
			"cam0_pnd0", "cam0_pnd1",
			"cam1_rst0", "cam1_rst1",
			"cam1_pnd0", "cam1_pnd1",
			"cam2_rst0", "cam2_rst1",
			"cam2_pnd0", "cam2_pnd1",
			"cam_ldo_main2_vcamd_0", "cam_ldo_main2_vcamd_1",
			"cam_ldo_main2_vcama_0", "cam_ldo_main2_vcama_1",
			"cam0_mclk_off", "cam0_mclk_on",
			"cam1_mclk_off", "cam1_mclk_on",
			"cam2_mclk_off", "cam2_mclk_on";
	pinctrl-0 = <&camera_pins_default>;
	pinctrl-1 = <&camera_pins_cam0_rst_0>;
	pinctrl-2 = <&camera_pins_cam0_rst_1>;
	pinctrl-3 = <&camera_pins_cam0_pnd_0>;
	pinctrl-4 = <&camera_pins_cam0_pnd_1>;
	pinctrl-5 = <&camera_pins_cam1_rst_0>;
	pinctrl-6 = <&camera_pins_cam1_rst_1>;
	pinctrl-7 = <&camera_pins_cam1_pnd_0>;
	pinctrl-8 = <&camera_pins_cam1_pnd_1>;
	pinctrl-9 = <&camera_pins_cam2_rst_0>;
	pinctrl-10 = <&camera_pins_cam2_rst_1>;
	pinctrl-11 = <&camera_pins_cam2_pnd_0>;
	pinctrl-12 = <&camera_pins_cam2_pnd_1>;
	pinctrl-13 = <&camera_pins_cam2_vcamd_0>;
	pinctrl-14 = <&camera_pins_cam2_vcamd_1>;
	pinctrl-15 = <&camera_pins_cam2_vcama_0>;
	pinctrl-16 = <&camera_pins_cam2_vcama_1>;
	pinctrl-17 = <&camera_pins_cam0_mclk_off>;
	pinctrl-18 = <&camera_pins_cam0_mclk_on>;
	pinctrl-19 = <&camera_pins_cam1_mclk_off>;
	pinctrl-20 = <&camera_pins_cam1_mclk_on>;
	pinctrl-21 = <&camera_pins_cam2_mclk_off>;
	pinctrl-22 = <&camera_pins_cam2_mclk_on>;

	status = "okay";
};

/* UART GPIO */
&apuart0 {
	pinctrl-names = "uart0_gpio_default",
			"uart0_rx_set",
			"uart0_rx_clear",
			"uart0_tx_set",
			"uart0_tx_clear",
			//#ifdef VENDOR_EDIT
			//PengNan@BSP.CHG.Basic, 2017/08/10, add for switch uart mode for chargerid.
			"uart0_rx_gpio",
			"uart0_tx_gpio";
			//#endif /*VENDOR_EDIT*/
	pinctrl-0 = <&uart0_gpio_def_cfg>;
	pinctrl-1 = <&uart0_rx_set_cfg>;
	pinctrl-2 = <&uart0_rx_clr_cfg>;
	pinctrl-3 = <&uart0_tx_set_cfg>;
	pinctrl-4 = <&uart0_tx_clr_cfg>;
	//#ifdef VENDOR_EDIT
	//Qiao.Hu@BSP.CHG.Basic, 2017/12/18, add for switch uart mode for chargerid.
	pinctrl-5 = <&uart0_rx_gpio_input2>;
	pinctrl-6 = <&uart0_tx_gpio_input2>;
	//#endif /*VENDOR_EDIT*/
	status = "okay";
};

&pio {
	/* UART GPIO Settings - Start */
	/* UART0: rx set, rx clear, tx clear, tx clear*/
	uart0_gpio_def_cfg:uart0gpiodefault {

	};
	uart0_rx_set_cfg:uart0_rx_set@gpio95 {
		pins_cmd_dat {
			pins = <PINMUX_GPIO95__FUNC_URXD0>;
		};
	};
	uart0_rx_clr_cfg:uart0_rx_clear@gpio95 {
		pins_cmd_dat {
			pins = <PINMUX_GPIO95__FUNC_GPIO95>;
			slew-rate = <1>;
			output-high;
		};
	};
	uart0_tx_set_cfg:uart0_tx_set@gpio96 {
		pins_cmd_dat {
			pins = <PINMUX_GPIO96__FUNC_UTXD0>;
		};
	};
	uart0_tx_clr_cfg:uart0_tx_clear@gpio96 {
		pins_cmd_dat {
			pins = <PINMUX_GPIO96__FUNC_GPIO96>;
			slew-rate = <1>;
			output-high;
		};
	};
	//#ifdef VENDOR_EDIT
	//Qiao.Hu@BSP.CHG.Basic, 2017/12/18, add for switch uart mode for chargerid.
	uart0_rx_gpio_input2:uart0_rx_gpio@gpio95 {
		pins_cmd_dat {
			pins = <PINMUX_GPIO95__FUNC_GPIO95>;
			input-enable;
			slew-rate = <0>;
			bias-disable;
		};
	};
	uart0_tx_gpio_input2:uart0_tx_gpio@gpio96 {
		pins_cmd_dat {
			pins = <PINMUX_GPIO96__FUNC_GPIO96>;
			input-enable;
			slew-rate = <0>;
			bias-disable;
		};
	};
	//#endif /*VENDOR_EDIT*/
};/* UART GPIO end */

/* IRTX GPIO Start */
&irtx_pwm {
	pinctrl-names = "irtx_gpio_led_default", "irtx_gpio_led_set";
	pinctrl-0 = <&irtx_gpio_led_default>;
	pinctrl-1 = <&irtx_gpio_led_set>;
	status = "okay";
};
&pio {
	/* IRTX GPIO Settings -Start */
	/* default: GPIO0, output, high */
	irtx_gpio_led_default:irtx_gpio_led_def@gpio90 {
		pins_cmd_dat {
			pins = <PINMUX_GPIO90__FUNC_GPIO90>;
			slew-rate = <1>;
			bias-disable;
			output-low;
			input-schmitt-enable = <0>;
		};
	};

	irtx_gpio_led_set:irtx_gpio_led_set@gpio90 {
		pins_cmd_dat {
			pins = <PINMUX_GPIO90__FUNC_PWM_A>;
			slew-rate = <1>;
			output-high;
		};
	};
}; /* IRTX GPIO Settings -End */

&mt6370_pmu {
	mt6370,intr_gpio_num = <10>; /* direct defined GPIO num */
	mt6370,intr_gpio = <&pio 10 0x0>;
};

&mt6370_typec {
	mt6370pd,intr_gpio_num = <41>; /* direct defined GPIO num */
	mt6370pd,intr_gpio = <&pio 41 0x0>;
};

/* USB TYPEC GPIO start */
/*&pio {
	usb_default: usb_default {
	};

	gpio_redriver_c1_init: c1_init {
		pins_cmd_dat {
			pins = <PINMUX_GPIO18__FUNC_GPIO18>;
			slew-rate = <1>;
			output-low;
		};
	};

	gpio_redriver_c1_low: c1_low {
		pins_cmd_dat {
			pins = <PINMUX_GPIO18__FUNC_GPIO18>;
			slew-rate = <1>;
			output-low;
		};
	};

	gpio_redriver_c1_hiz: c1_highz {
		pins_cmd_dat {
			pins = <PINMUX_GPIO18__FUNC_GPIO18>;
			slew-rate= <0>;
			bias-disable;
		};
	};

	gpio_redriver_c1_high: c1_high {
		pins_cmd_dat {
			pins = <PINMUX_GPIO18__FUNC_GPIO18>;
			slew-rate = <1>;
			output-high;
		};
	};

	gpio_redriver_c2_init: c2_init {
		pins_cmd_dat {
			pins = <PINMUX_GPIO17__FUNC_GPIO17>;
			slew-rate = <1>;
			output-low;
		};
	};

	gpio_redriver_c2_low: c2_low {
		pins_cmd_dat {
			pins = <PINMUX_GPIO17__FUNC_GPIO17>;
			slew-rate = <1>;
			output-low;
		};
	};

	gpio_redriver_c2_hiz: c2_highz {
		pins_cmd_dat {
			pins = <PINMUX_GPIO17__FUNC_GPIO17>;
			slew-rate= <0>;
			bias-disable;
		};
	};

	gpio_redriver_c2_high: c2_high {
		pins_cmd_dat {
			pins = <PINMUX_GPIO17__FUNC_GPIO17>;
			slew-rate = <1>;
			output-high;
		};
	};

	gpio_u3_switch_sel1: u3_sw_sel1 {
		pins_cmd_dat {
			pins = <PINMUX_GPIO177__FUNC_GPIO177>;
			slew-rate = <1>;
			output-low;
		};
	};

	gpio_u3_switch_sel2: u3_sw_sel2 {
		pins_cmd_dat {
			pins = <PINMUX_GPIO177__FUNC_GPIO177>;
			slew-rate = <1>;
			output-high;
		};
	};

	gpio_u3_switch_enable: u3_sw_en {
	};

	gpio_u3_switch_disable: u3_sw_dis {
	};
};

&usb_c_pinctrl {
	pinctrl-names = "usb_default",
		"redriver_c1_init",
		"redriver_c1_low",
		"redriver_c1_hiz",
		"redriver_c1_high",
		"redriver_c2_init",
		"redriver_c2_low",
		"redriver_c2_hiz",
		"redriver_c2_high",
		"u3_switch_sel1",
		"u3_switch_sel2",
		"u3_switch_enable",
		"u3_switch_disable";

	pinctrl-0 = <&usb_default>;
	pinctrl-1 = <&gpio_redriver_c1_init>;
	pinctrl-2 = <&gpio_redriver_c1_low>;
	pinctrl-3 = <&gpio_redriver_c1_hiz>;
	pinctrl-4 = <&gpio_redriver_c1_high>;
	pinctrl-5 = <&gpio_redriver_c2_init>;
	pinctrl-6 = <&gpio_redriver_c2_low>;
	pinctrl-7 = <&gpio_redriver_c2_hiz>;
	pinctrl-8 = <&gpio_redriver_c2_high>;
	pinctrl-9 = <&gpio_u3_switch_sel1>;
	pinctrl-10 = <&gpio_u3_switch_sel2>;
	pinctrl-11 = <&gpio_u3_switch_enable>;
	pinctrl-12 = <&gpio_u3_switch_disable>;
	status = "okay";
*/
//	usb_switch-data {
//		en_pin_num = <0>;
//		en_pin_val = <0>; /*DISABLE=0 ENABLE=1*/
//		sel_pin_num = <177>;
//		sel_pin_val = <1>; /*CC1=1, CC2=2*/
//		c1_pin_num = <18>;
//		c1_pin_val = <2>; /*Low=0, HighZ=1, High=2*/
//		c2_pin_num = <17>;
//		c2_pin_val = <1>;
//	};
//};

/* USB TYPEC GPIO end */

//#ifdef VENDOR_EDIT
/* Bin.Li@EXP.BSP.bootloader.bootflow, 2017/05/16, Add volume up and down */
&keypad {
	keypad,volume-up	= <&pio 20 0x00>;
	keypad,volume-down	= <&pio 94 0x00>;
	pinctrl-names = "volume_up_as_int", "volume_down_as_int";
	pinctrl-0 = <&volume_up_gpio_eint>;
	pinctrl-1 = <&volume_down_gpio_eint>;
	status = "okay";
};

&pio {
	volume_up_gpio_eint:volume_up@0{
		pins_cmd_dat {
			pins = <PINMUX_GPIO20__FUNC_GPIO20>;
			slew-rate = <0>;  /*direction 0:in, 1:out*/
			bias-pull-up = <00>;
			input-enable;
		};
	};
	volume_down_gpio_eint:volume_down@0{
		pins_cmd_dat {
			pins = <PINMUX_GPIO94__FUNC_GPIO94>;
			slew-rate = <0>;  /*direction 0:in, 1:out*/
			bias-pull-up = <00>;
			input-enable;
		};
	};
};
//#endif /*VENDOR_EDIT*/

//#ifdef VENDOR_EDIT
/* Bin.Li@EXP.BSP.bootloader.bootflow, 2017/05/15, Add for T-card ldo */
&msdc1{
	pinctrl-names = "msdc1_on","msdc1_off";
	pinctrl-0 = <&msdc1_on>;
	pinctrl-1 = <&msdc1_off>;
	status = "okay";
};
&pio {
	msdc1_on:sd0@0{
		pins_cmd_dat {
			pins = <PINMUX_GPIO90__FUNC_GPIO90>;
			slew-rate = <1>;
			output-high;
		};
    };
	msdc1_off: sd0@1 {
		pins_cmd_dat {
			pins = <PINMUX_GPIO90__FUNC_GPIO90>;
			slew-rate = <1>;
			output-low;
		};
	};
};
//#endif /*VENDOR_EDIT*/
//#ifndef VENDOR_EDIT
/*	Fuchun.Liao@BSP.CHG.Basic 2017/11/09 modify to use bq24190 charger
&charger {
	algorithm_name = "DualSwitchCharging";
	chg1_ta_ac_charger_current = <2000000>;
	chg2_ta_ac_charger_current = <2000000>;
};
*/
//#endif /* VENDOR_EDIT */

//#ifndef VENDOR_EDIT
//Fuchun.Liao@BSP.CHG.Basic 2017/11/18 modify for use bq24190 charger
//&i2c6 {
//	rt9465@4b {
//		compatible = "richtek,rt9465";
//		reg = <0x4b>;
//		status = "okay";
//		rt,en_gpio_num = <179>;
//		rt,en_gpio = <&pio 179 0x0>;
//		mt6306_en_pin = <1>;
//		rt,intr_gpio_num = <9>; /* direct defined GPIO num */
//		rt,intr_gpio = <&pio 9 0x0>;
//		interrupt-names = "wdtmri";
//		charger_name = "secondary_chg";
//		ichg = <1500000>; /* uA */
//		mivr = <4500000>; /* uV */
//		cv = <4550000>; /* uV */
//		ieoc = <700000>; /* uA */
//		safety_timer = <12>; /* hour */
//		en_st; /* safety timer */
//		/* en_te; */
//		en_wdt;
//	};
//};
//#endif /* VENDOR_EDIT */

//ifdef VENDOR_EDIT
/* Bin.Li@PSW.BSP.Fingerprint.Basic, 2017/11/22, Add for FPC driver baseon trustonic tee */
/*the id config to project dts.*/
&pio{
	gpio_id0_default: gpio_id0_default {
		pins_cmd_dat {
			pins = <PINMUX_GPIO177__FUNC_GPIO177>;
			slew-rate = <0>;
			bias-pull-up = <00>;
			input-enable;
		};
	};

	gpio_id1_default: gpio_id1_default {
		pins_cmd_dat {
			pins = <PINMUX_GPIO159__FUNC_GPIO159>;
			slew-rate = <0>;
			bias-pull-up = <00>;
			input-enable;
		};
	};

	gpio_id2_default: gpio_id2_default {
		pins_cmd_dat {
			pins = <PINMUX_GPIO175__FUNC_GPIO175>;
			slew-rate = <0>;
			bias-pull-up = <00>;
			input-enable;
		};
	};
};

&oppo_fp_common {
	oppo,fp-id0 = <&pio 177 0x00>;
	oppo,fp-id1 = <&pio 159 0x00>;
	oppo,fp-id2 = <&pio 175 0x00>;
	pinctrl-names = "default";
	pinctrl-0 = <&gpio_id0_default>, <&gpio_id1_default>, <&gpio_id2_default>;
};
//#endif/*VENDOR_EDIT*/

//ifdef VENDOR_EDIT
/* Bin.Li@EXP.BSP.bootloader.bootflow, 2017/07/07, Add device-info */
&oppo_devinfo {
	Hw,sub_hwid_1 = <&pio 176 0x00>;
	Hw,sub_hwid_2 = <&pio 58 0x00>;
	Hw,main_hwid_5 = <&pio 92 0x00>;
	Hw,main_hwid_6 = <&pio 15 0x00>;
	pinctrl-names = "default", "hw_sub_id_sleep", "hw_sub_id_active", 
					"hw_main_id5_active", "hw_main_id6_active";
	pinctrl-0 = <&hw_pins_default>;
	pinctrl-1 = <&hw_pins_sub_id1_sleep &hw_pins_sub_id2_sleep>;
	pinctrl-2 = <&hw_pins_sub_id1_active &hw_pins_sub_id2_active>;
	pinctrl-3 = <&hw_main_id5_active>;
	pinctrl-4 = <&hw_main_id6_active>;
};

&pio {
	hw_pins_default:default@hw_sub_id {
	};

	hw_pins_sub_id1_sleep:sleep@id1 {
			pins_cmd_dat {
			pins = <PINMUX_GPIO176__FUNC_GPIO176>;
			slew-rate = <0>;
			bias-pull-down = <00>;
			input-enable;
			};
	};

	hw_pins_sub_id2_sleep:sleep@id2 {
			pins_cmd_dat {
			pins = <PINMUX_GPIO58__FUNC_GPIO58>;
			bias-pull-down = <00>;
			input-enable;
			};
	};

	hw_pins_sub_id1_active:active@id1 {
		pins_cmd_dat {
		pins = <PINMUX_GPIO176__FUNC_GPIO176>;
			slew-rate = <0>;
			bias-pull-up = <00>;
			input-enable;
			};
	};
	hw_pins_sub_id2_active:active@id2 {
		pins_cmd_dat {
		pins = <PINMUX_GPIO58__FUNC_GPIO58>;
			slew-rate = <0>;
			bias-pull-up = <00>;
			input-enable;
			};
	};

	hw_main_id5_active:active@id5 {
		pins_cmd_dat {
		pins = <PINMUX_GPIO92__FUNC_GPIO92>;
			slew-rate = <0>;
			bias-pull-down = <101>;
			input-enable;
			};
	};

	hw_main_id6_active:active@id6 {
		pins_cmd_dat {
		pins = <PINMUX_GPIO15__FUNC_GPIO15>;
			slew-rate = <0>;
			bias-pull-down = <00>;
			input-enable;
			};
	};
};
//endif

//#ifdef VENDOR_EDIT
//Fuchun.Liao@BSP.CHG.Basic 2017/11/24 modify for oppo dws
#include <oppo6771_17061/cust.dtsi>
//#endif /* VENDOR_EDIT */
/*End of this file, DO NOT ADD ANYTHING HERE*/


